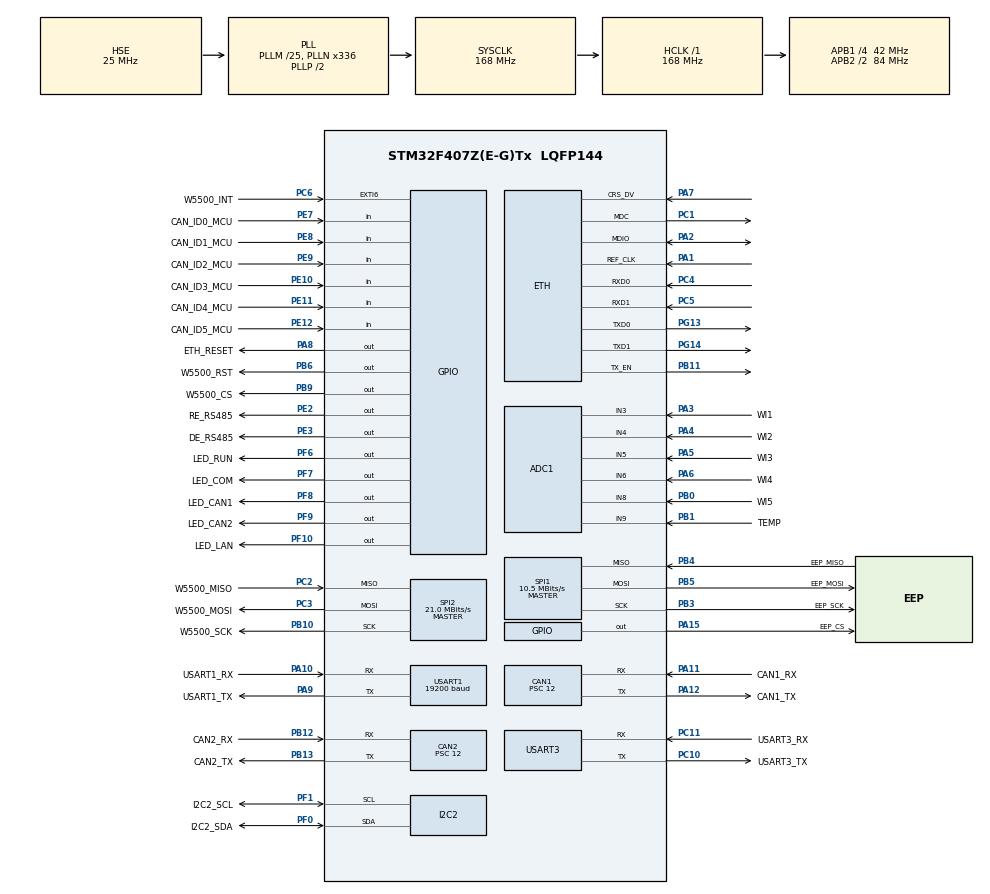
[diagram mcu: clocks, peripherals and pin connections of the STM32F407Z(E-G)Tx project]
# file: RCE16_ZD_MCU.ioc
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ADC1.Channel-0\#ChannelRegularConversion=ADC_CHANNEL_3
ADC1.Channel-1\#ChannelRegularConversion=ADC_CHANNEL_4
ADC1.Channel-2\#ChannelRegularConversion=ADC_CHANNEL_5
ADC1.Channel-3\#ChannelRegularConversion=ADC_CHANNEL_6
ADC1.Channel-4\#ChannelRegularConversion=ADC_CHANNEL_8
ADC1.Channel-5\#ChannelRegularConversion=ADC_CHANNEL_9
ADC1.ClockPrescaler=ADC_CLOCK_SYNC_PCLK_DIV4
ADC1.ContinuousConvMode=DISABLE
ADC1.DMAContinuousRequests=ENABLE
ADC1.DiscontinuousConvMode=ENABLE
ADC1.EOCSelection=ADC_EOC_SEQ_CONV
ADC1.InjNumberOfConversion=0
ADC1.NbrOfConversion=6
ADC1.NbrOfConversionFlag=1
ADC1.NbrOfDiscConversion=6
ADC1.Rank-0\#ChannelRegularConversion=1
ADC1.Rank-1\#ChannelRegularConversion=2
ADC1.Rank-2\#ChannelRegularConversion=3
ADC1.Rank-3\#ChannelRegularConversion=4
ADC1.Rank-4\#ChannelRegularConversion=5
ADC1.Rank-5\#ChannelRegularConversion=6
ADC1.SamplingTime-0\#ChannelRegularConversion=ADC_SAMPLETIME_56CYCLES
ADC1.SamplingTime-1\#ChannelRegularConversion=ADC_SAMPLETIME_56CYCLES
ADC1.SamplingTime-2\#ChannelRegularConversion=ADC_SAMPLETIME_56CYCLES
ADC1.SamplingTime-3\#ChannelRegularConversion=ADC_SAMPLETIME_56CYCLES
ADC1.SamplingTime-4\#ChannelRegularConversion=ADC_SAMPLETIME_56CYCLES
ADC1.SamplingTime-5\#ChannelRegularConversion=ADC_SAMPLETIME_56CYCLES
ADC1.ScanConvMode=ENABLE
ADC1.master=1
CAN1.ABOM=ENABLE
CAN1.AWUM=ENABLE
CAN1.BS1=CAN_BS1_5TQ
CAN1.BS2=CAN_BS2_8TQ
CAN1.CalculateBaudRate=250000
CAN1.CalculateTimeBit=4000
CAN1.CalculateTimeQuantum=285.7142857142857
CAN1.NART=DISABLE
CAN1.Prescaler=12
CAN1.SJW=CAN_SJW_1TQ
CAN2.ABOM=ENABLE
CAN2.AWUM=ENABLE
CAN2.BS1=CAN_BS1_5TQ
CAN2.BS2=CAN_BS2_8TQ
CAN2.CalculateBaudRate=250000
CAN2.CalculateTimeBit=4000
CAN2.CalculateTimeQuantum=285.7142857142857
CAN2.Prescaler=12
Dma.ADC1.0.Direction=DMA_PERIPH_TO_MEMORY
Dma.ADC1.0.FIFOMode=DMA_FIFOMODE_DISABLE
Dma.ADC1.0.Instance=DMA2_Stream0
Dma.ADC1.0.MemDataAlignment=DMA_MDATAALIGN_HALFWORD
Dma.ADC1.0.MemInc=DMA_MINC_ENABLE
Dma.ADC1.0.Mode=DMA_CIRCULAR
Dma.ADC1.0.PeriphDataAlignment=DMA_PDATAALIGN_HALFWORD
Dma.ADC1.0.PeriphInc=DMA_PINC_DISABLE
Dma.ADC1.0.Priority=DMA_PRIORITY_LOW
Dma.I2C2_RX.1.Direction=DMA_PERIPH_TO_MEMORY
Dma.I2C2_RX.1.FIFOMode=DMA_FIFOMODE_DISABLE
Dma.I2C2_RX.1.Instance=DMA1_Stream2
Dma.I2C2_RX.1.MemDataAlignment=DMA_MDATAALIGN_BYTE
Dma.I2C2_RX.1.MemInc=DMA_MINC_ENABLE
Dma.I2C2_RX.1.Mode=DMA_NORMAL
Dma.I2C2_RX.1.PeriphDataAlignment=DMA_PDATAALIGN_BYTE
Dma.I2C2_RX.1.PeriphInc=DMA_PINC_DISABLE
Dma.I2C2_RX.1.Priority=DMA_PRIORITY_LOW
Dma.Request0=ADC1
Dma.Request1=I2C2_RX
Dma.Request2=USART1_RX
Dma.Request3=USART1_TX
Dma.Request4=SPI2_RX
Dma.Request5=SPI2_TX
Dma.Request6=SPI1_RX
Dma.Request7=SPI1_TX
Dma.SPI1_RX.6.Direction=DMA_PERIPH_TO_MEMORY
Dma.SPI1_RX.6.FIFOMode=DMA_FIFOMODE_DISABLE
Dma.SPI1_RX.6.Instance=DMA2_Stream2
Dma.SPI1_RX.6.MemDataAlignment=DMA_MDATAALIGN_BYTE
Dma.SPI1_RX.6.MemInc=DMA_MINC_ENABLE
Dma.SPI1_RX.6.Mode=DMA_NORMAL
Dma.SPI1_RX.6.PeriphDataAlignment=DMA_PDATAALIGN_BYTE
Dma.SPI1_RX.6.PeriphInc=DMA_PINC_DISABLE
Dma.SPI1_RX.6.Priority=DMA_PRIORITY_LOW
Dma.SPI1_TX.7.Direction=DMA_MEMORY_TO_PERIPH
Dma.SPI1_TX.7.FIFOMode=DMA_FIFOMODE_DISABLE
Dma.SPI1_TX.7.Instance=DMA2_Stream3
Dma.SPI1_TX.7.MemDataAlignment=DMA_MDATAALIGN_BYTE
Dma.SPI1_TX.7.MemInc=DMA_MINC_ENABLE
Dma.SPI1_TX.7.Mode=DMA_NORMAL
Dma.SPI1_TX.7.PeriphDataAlignment=DMA_PDATAALIGN_BYTE
Dma.SPI1_TX.7.PeriphInc=DMA_PINC_DISABLE
Dma.SPI1_TX.7.Priority=DMA_PRIORITY_LOW
Dma.SPI2_RX.4.Direction=DMA_PERIPH_TO_MEMORY
Dma.SPI2_RX.4.FIFOMode=DMA_FIFOMODE_DISABLE
Dma.SPI2_RX.4.Instance=DMA1_Stream3
Dma.SPI2_RX.4.MemDataAlignment=DMA_MDATAALIGN_BYTE
Dma.SPI2_RX.4.MemInc=DMA_MINC_ENABLE
Dma.SPI2_RX.4.Mode=DMA_NORMAL
Dma.SPI2_RX.4.PeriphDataAlignment=DMA_PDATAALIGN_BYTE
Dma.SPI2_RX.4.PeriphInc=DMA_PINC_DISABLE
Dma.SPI2_RX.4.Priority=DMA_PRIORITY_LOW
Dma.SPI2_TX.5.Direction=DMA_MEMORY_TO_PERIPH
Dma.SPI2_TX.5.FIFOMode=DMA_FIFOMODE_DISABLE
Dma.SPI2_TX.5.Instance=DMA1_Stream4
Dma.SPI2_TX.5.MemDataAlignment=DMA_MDATAALIGN_BYTE
Dma.SPI2_TX.5.MemInc=DMA_MINC_ENABLE
Dma.SPI2_TX.5.Mode=DMA_NORMAL
Dma.SPI2_TX.5.PeriphDataAlignment=DMA_PDATAALIGN_BYTE
Dma.SPI2_TX.5.PeriphInc=DMA_PINC_DISABLE
Dma.SPI2_TX.5.Priority=DMA_PRIORITY_LOW
Dma.USART1_RX.2.Direction=DMA_PERIPH_TO_MEMORY
Dma.USART1_RX.2.FIFOMode=DMA_FIFOMODE_DISABLE
Dma.USART1_RX.2.Instance=DMA2_Stream5
Dma.USART1_RX.2.MemDataAlignment=DMA_MDATAALIGN_BYTE
Dma.USART1_RX.2.MemInc=DMA_MINC_ENABLE
Dma.USART1_RX.2.Mode=DMA_CIRCULAR
Dma.USART1_RX.2.PeriphDataAlignment=DMA_PDATAALIGN_BYTE
Dma.USART1_RX.2.PeriphInc=DMA_PINC_DISABLE
Dma.USART1_RX.2.Priority=DMA_PRIORITY_LOW
Dma.USART1_TX.3.Direction=DMA_MEMORY_TO_PERIPH
Dma.USART1_TX.3.FIFOMode=DMA_FIFOMODE_DISABLE
Dma.USART1_TX.3.Instance=DMA2_Stream7
Dma.USART1_TX.3.MemDataAlignment=DMA_MDATAALIGN_BYTE
Dma.USART1_TX.3.MemInc=DMA_MINC_ENABLE
Dma.USART1_TX.3.Mode=DMA_NORMAL
Dma.USART1_TX.3.PeriphDataAlignment=DMA_PDATAALIGN_BYTE
Dma.USART1_TX.3.PeriphInc=DMA_PINC_DISABLE
Dma.USART1_TX.3.Priority=DMA_PRIORITY_LOW
ETH.MediaInterface=HAL_ETH_RMII_MODE
ETH.RxMode=ETH_RXPOLLING_MODE
LWIP.BSP.number=1
LWIP.GATEWAY_ADDRESS=192.168.000.001
LWIP.IP_ADDRESS=192.168.000.111
LWIP.LWIP_DHCP=0
LWIP.LWIP_UDP=1
LWIP.NETMASK_ADDRESS=255.255.255.000
LWIP.Version=v2.1.2_Cube
LWIP0.BSP.STBoard=false
LWIP0.BSP.api=BSP_COMPONENT_DRIVER
LWIP0.BSP.component=LAN8742
LWIP0.BSP.instance=LAN8742
LWIP0.BSP.name=Driver_PHY
LWIP0.BSP.semaphore=S_LAN8742
LWIP0.BSP.solution=LAN8742
Mcu.Family=STM32F4
Mcu.Name=STM32F407Z(E-G)Tx
Mcu.Package=LQFP144
NVIC.CAN1_RX0_IRQn=true\:0\:0\:false\:false\:true\:true\:true\:true
NVIC.CAN2_RX0_IRQn=true\:0\:0\:false\:false\:true\:true\:true\:true
NVIC.DMA1_Stream2_IRQn=true\:0\:0\:false\:false\:true\:false\:true\:true
NVIC.DMA1_Stream3_IRQn=true\:0\:0\:false\:false\:true\:false\:true\:true
NVIC.DMA1_Stream4_IRQn=true\:0\:0\:false\:false\:true\:false\:true\:true
NVIC.DMA2_Stream0_IRQn=true\:0\:0\:false\:false\:true\:false\:true\:true
NVIC.DMA2_Stream2_IRQn=true\:0\:0\:false\:false\:true\:false\:true\:true
NVIC.DMA2_Stream3_IRQn=true\:0\:0\:false\:false\:true\:false\:true\:true
NVIC.DMA2_Stream5_IRQn=true\:0\:0\:false\:false\:true\:false\:true\:true
NVIC.DMA2_Stream7_IRQn=true\:0\:0\:false\:false\:true\:false\:true\:true
NVIC.ETH_IRQn=true\:0\:0\:false\:false\:true\:true\:true\:true
NVIC.ETH_WKUP_IRQn=true\:0\:0\:false\:false\:true\:true\:true\:true
NVIC.I2C2_EV_IRQn=true\:0\:0\:false\:false\:true\:true\:true\:true
NVIC.PriorityGroup=NVIC_PRIORITYGROUP_4
NVIC.SPI1_IRQn=true\:0\:0\:false\:false\:true\:true\:true\:true
NVIC.SPI2_IRQn=true\:0\:0\:false\:false\:true\:true\:true\:true
NVIC.USART1_IRQn=true\:0\:0\:false\:false\:true\:true\:true\:true
PA1.Mode=RMII
PA1.Signal=ETH_REF_CLK
PA10.GPIO_Label=USART1_RX
PA10.Mode=Asynchronous
PA10.Signal=USART1_RX
PA11.GPIO_Label=CAN1_RX
PA11.Mode=CAN_Activate
PA11.Signal=CAN1_RX
PA12.GPIO_Label=CAN1_TX
PA12.Mode=CAN_Activate
PA12.Signal=CAN1_TX
PA13.Mode=Serial_Wire
PA13.Signal=SYS_JTMS-SWDIO
PA14.Mode=Serial_Wire
PA14.Signal=SYS_JTCK-SWCLK
PA15.GPIO_Label=EEP_CS
PA15.Signal=GPIO_Output
PA2.Mode=RMII
PA2.Signal=ETH_MDIO
PA3.GPIO_Label=WI1
PA3.Signal=ADCx_IN3
PA4.GPIO_Label=WI2
PA4.Signal=ADCx_IN4
PA5.GPIO_Label=WI3
PA5.Signal=ADCx_IN5
PA6.GPIO_Label=WI4
PA6.Signal=ADCx_IN6
PA7.Mode=RMII
PA7.Signal=ETH_CRS_DV
PA8.GPIO_Label=ETH_RESET
PA8.GPIO_Speed=GPIO_SPEED_FREQ_LOW
PA8.PinState=GPIO_PIN_SET
PA8.Signal=GPIO_Output
PA9.GPIO_Label=USART1_TX
PA9.Mode=Asynchronous
PA9.Signal=USART1_TX
PB0.GPIO_Label=WI5
PB0.Signal=ADCx_IN8
PB1.GPIO_Label=TEMP
PB1.Signal=ADCx_IN9
PB10.GPIO_Label=W5500_SCK
PB10.Mode=Full_Duplex_Master
PB10.Signal=SPI2_SCK
PB11.Mode=RMII
PB11.Signal=ETH_TX_EN
PB12.GPIO_Label=CAN2_RX
PB12.Mode=CAN_Activate
PB12.Signal=CAN2_RX
PB13.GPIO_Label=CAN2_TX
PB13.Mode=CAN_Activate
PB13.Signal=CAN2_TX
PB3.GPIO_Label=EEP_SCK
PB3.Mode=Full_Duplex_Master
PB3.Signal=SPI1_SCK
PB4.GPIO_Label=EEP_MISO
PB4.Mode=Full_Duplex_Master
PB4.Signal=SPI1_MISO
PB5.GPIO_Label=EEP_MOSI
PB5.Mode=Full_Duplex_Master
PB5.Signal=SPI1_MOSI
PB6.GPIO_Label=W5500_RST
PB6.PinState=GPIO_PIN_SET
PB6.Signal=GPIO_Output
PB9.GPIO_Label=W5500_CS
PB9.Signal=GPIO_Output
PC1.Mode=RMII
PC1.Signal=ETH_MDC
PC10.GPIO_Label=USART3_TX
PC10.Mode=Asynchronous
PC10.Signal=USART3_TX
PC11.GPIO_Label=USART3_RX
PC11.Mode=Asynchronous
PC11.Signal=USART3_RX
PC2.GPIO_Label=W5500_MISO
PC2.Mode=Full_Duplex_Master
PC2.Signal=SPI2_MISO
PC3.GPIO_Label=W5500_MOSI
PC3.Mode=Full_Duplex_Master
PC3.Signal=SPI2_MOSI
PC4.Mode=RMII
PC4.Signal=ETH_RXD0
PC5.Mode=RMII
PC5.Signal=ETH_RXD1
PC6.GPIO_Label=W5500_INT
PC6.GPIO_ModeDefaultEXTI=GPIO_MODE_IT_FALLING
PC6.Signal=GPXTI6
PE10.GPIO_Label=CAN_ID3_MCU
PE10.Signal=GPIO_Input
PE11.GPIO_Label=CAN_ID4_MCU
PE11.Signal=GPIO_Input
PE12.GPIO_Label=CAN_ID5_MCU
PE12.Signal=GPIO_Input
PE2.GPIO_Label=RE_RS485
PE2.GPIO_Speed=GPIO_SPEED_FREQ_LOW
PE2.PinState=GPIO_PIN_SET
PE2.Signal=GPIO_Output
PE3.GPIO_Label=DE_RS485
PE3.Signal=GPIO_Output
PE7.GPIO_Label=CAN_ID0_MCU
PE7.Signal=GPIO_Input
PE8.GPIO_Label=CAN_ID1_MCU
PE8.Signal=GPIO_Input
PE9.GPIO_Label=CAN_ID2_MCU
PE9.Signal=GPIO_Input
PF0.GPIO_Label=I2C2_SDA
PF0.Mode=I2C
PF0.Signal=I2C2_SDA
PF1.GPIO_Label=I2C2_SCL
PF1.Mode=I2C
PF1.Signal=I2C2_SCL
PF10.GPIO_Label=LED_LAN
PF10.Signal=GPIO_Output
PF6.GPIO_Label=LED_RUN
PF6.Signal=GPIO_Output
PF7.GPIO_Label=LED_COM
PF7.Signal=GPIO_Output
PF8.GPIO_Label=LED_CAN1
PF8.Signal=GPIO_Output
PF9.GPIO_Label=LED_CAN2
PF9.Signal=GPIO_Output
PG13.Mode=RMII
PG13.Signal=ETH_TXD0
PG14.Mode=RMII
PG14.Signal=ETH_TXD1
PH0-OSC_IN.Mode=HSE-External-Oscillator
PH0-OSC_IN.Signal=RCC_OSC_IN
PH1-OSC_OUT.Mode=HSE-External-Oscillator
PH1-OSC_OUT.Signal=RCC_OSC_OUT
ProjectManager.HeapSize=0x800
ProjectManager.StackSize=0x800
ProjectManager.TargetToolchain=MDK-ARM V5.32
RCC.48MHZClocksFreq_Value=84000000
RCC.AHBFreq_Value=168000000
RCC.APB1CLKDivider=RCC_HCLK_DIV4
RCC.APB1Freq_Value=42000000
RCC.APB1TimFreq_Value=84000000
RCC.APB2CLKDivider=RCC_HCLK_DIV2
RCC.APB2Freq_Value=84000000
RCC.APB2TimFreq_Value=168000000
RCC.CortexFreq_Value=168000000
RCC.HCLKFreq_Value=168000000
RCC.HSE_VALUE=25000000
RCC.HSICalibrationValue=16
RCC.HSI_VALUE=16000000
RCC.LSE_VALUE=32768
RCC.PLLM=25
RCC.PLLN=336
RCC.PLLSourceVirtual=RCC_PLLSOURCE_HSE
RCC.SYSCLKFreq_VALUE=168000000
RCC.SYSCLKSource=RCC_SYSCLKSOURCE_PLLCLK
RCC.VCOOutputFreq_Value=336000000
SH.ADCx_IN3.0=ADC1_IN3,IN3
SH.ADCx_IN4.0=ADC1_IN4,IN4
SH.ADCx_IN5.0=ADC1_IN5,IN5
SH.ADCx_IN6.0=ADC1_IN6,IN6
SH.ADCx_IN8.0=ADC1_IN8,IN8
SH.ADCx_IN9.0=ADC1_IN9,IN9
SPI1.BaudRatePrescaler=SPI_BAUDRATEPRESCALER_8
SPI1.CLKPhase=SPI_PHASE_2EDGE
SPI1.CLKPolarity=SPI_POLARITY_HIGH
SPI1.CalculateBaudRate=10.5 MBits/s
SPI1.Direction=SPI_DIRECTION_2LINES
SPI1.Mode=SPI_MODE_MASTER
SPI1.VirtualType=VM_MASTER
SPI2.BaudRatePrescaler=SPI_BAUDRATEPRESCALER_2
SPI2.CLKPhase=SPI_PHASE_2EDGE
SPI2.CLKPolarity=SPI_POLARITY_HIGH
SPI2.CalculateBaudRate=21.0 MBits/s
SPI2.Direction=SPI_DIRECTION_2LINES
SPI2.Mode=SPI_MODE_MASTER
SPI2.VirtualType=VM_MASTER
USART1.BaudRate=19200
USART1.VirtualMode=VM_ASYNC
USART3.VirtualMode=VM_ASYNC
VP_LWIP_VS_Enabled.Mode=Enabled
board=custom

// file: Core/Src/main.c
/* USER CODE BEGIN Header */
/**
  ******************************************************************************
  * @file           : main.c
  * @brief          : Main program body
  ******************************************************************************
  * @attention
  *
  * Copyright (c) 2024 STMicroelectronics.
  * All rights reserved.
  *
  * This software is licensed under terms that can be found in the LICENSE file
  * in the root directory of this software component.
  * If no LICENSE file comes with this software, it is provided AS-IS.
  *
  ******************************************************************************
  */
/* USER CODE END Header */
#include "main.h"
#include "adc.h"
#include "can.h"
#include "dma.h"
#include "i2c.h"
#include "lwip.h"
#include "spi.h"
#include "usart.h"
#include "gpio.h"

/* USER CODE BEGIN Includes */
#include "sys_app.h"
#include "lwip.h"
/* USER CODE END Includes */

void SystemClock_Config(void);

int main(void)
{

  /* MCU Configuration--------------------------------------------------------*/

  /* Reset of all peripherals, Initializes the Flash interface and the Systick. */
  HAL_Init();

  /* Configure the system clock */
  SystemClock_Config();

  /* Initialize all configured peripherals */
  MX_GPIO_Init();
  MX_DMA_Init();
  MX_ADC1_Init();
  MX_CAN1_Init();
  MX_CAN2_Init();
  MX_I2C2_Init();
  MX_SPI1_Init();
  MX_SPI2_Init();
  MX_USART1_UART_Init();
  MX_USART3_UART_Init();
  MX_LWIP_Init();
  /* USER CODE BEGIN 2 */
	UserLog("bsp init success");
	rc_sys_app_init();
  /* USER CODE END 2 */

  /* Infinite loop */
  while (1)
  {

    /* USER CODE BEGIN 3 */
		sys_app_poll();
  }
  /* USER CODE END 3 */
}

void SystemClock_Config(void)
{
  RCC_OscInitTypeDef RCC_OscInitStruct = {0};
  RCC_ClkInitTypeDef RCC_ClkInitStruct = {0};

  /** Configure the main internal regulator output voltage
  */
  __HAL_RCC_PWR_CLK_ENABLE();
  __HAL_PWR_VOLTAGESCALING_CONFIG(PWR_REGULATOR_VOLTAGE_SCALE1);

  /** Initializes the RCC Oscillators according to the specified parameters
  * in the RCC_OscInitTypeDef structure.
  */
  RCC_OscInitStruct.OscillatorType = RCC_OSCILLATORTYPE_HSE;
  RCC_OscInitStruct.HSEState = RCC_HSE_ON;
  RCC_OscInitStruct.PLL.PLLState = RCC_PLL_ON;
  RCC_OscInitStruct.PLL.PLLSource = RCC_PLLSOURCE_HSE;
  RCC_OscInitStruct.PLL.PLLM = 25;
  RCC_OscInitStruct.PLL.PLLN = 336;
  RCC_OscInitStruct.PLL.PLLP = RCC_PLLP_DIV2;
  RCC_OscInitStruct.PLL.PLLQ = 4;
  if (HAL_RCC_OscConfig(&RCC_OscInitStruct) != HAL_OK)
  {
    Error_Handler();
  }

  /** Initializes the CPU, AHB and APB buses clocks
  */
  RCC_ClkInitStruct.ClockType = RCC_CLOCKTYPE_HCLK|RCC_CLOCKTYPE_SYSCLK
                              |RCC_CLOCKTYPE_PCLK1|RCC_CLOCKTYPE_PCLK2;
  RCC_ClkInitStruct.SYSCLKSource = RCC_SYSCLKSOURCE_PLLCLK;
  RCC_ClkInitStruct.AHBCLKDivider = RCC_SYSCLK_DIV1;
  RCC_ClkInitStruct.APB1CLKDivider = RCC_HCLK_DIV4;
  RCC_ClkInitStruct.APB2CLKDivider = RCC_HCLK_DIV2;

  if (HAL_RCC_ClockConfig(&RCC_ClkInitStruct, FLASH_LATENCY_5) != HAL_OK)
  {
    Error_Handler();
  }
}

void Error_Handler(void)
{
  __disable_irq();
  while (1)
  {
  }
}
